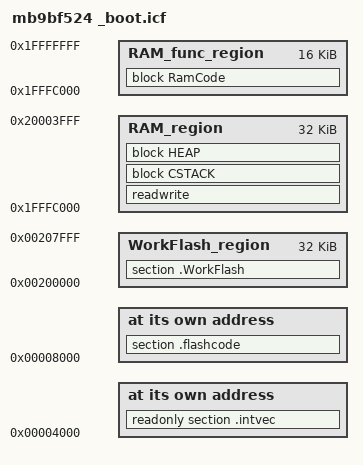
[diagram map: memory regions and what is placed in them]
/*###ICF### Section handled by ICF editor, don't touch! ****/
/*-Editor annotation file-*/
/* IcfEditorFile="$TOOLKIT_DIR$\config\ide\IcfEditor\cortex_v1_0.xml" */
/*-Specials-*/
define symbol __ICFEDIT_intvec_start__ = 0x4000;
/*-Memory Regions-*/
define symbol __ICFEDIT_region_ROM_start__ = 0x4000;
define symbol __ICFEDIT_region_ROM_end__   = 0x00001fff;
define symbol __ICFEDIT_region_RAM_start__ = 0x1FFFC000;
define symbol __ICFEDIT_region_RAM_end__   = 0x20003FFF;

/*-Sizes-*/
define symbol __ICFEDIT_size_cstack__ = 0x400;
define symbol __ICFEDIT_size_heap__   = 0x800;
/**** End of ICF editor section. ###ICF###*/

define symbol WorkFlash_region_start = 0x00200000;
define symbol WorkFlash_region_end   = 0x00207FFF;

define memory mem with size = 4G;
define region ROM_region   = mem:[from __ICFEDIT_region_ROM_start__   to __ICFEDIT_region_ROM_end__];
define region RAM_region   = mem:[from __ICFEDIT_region_RAM_start__   to __ICFEDIT_region_RAM_end__];
define region WorkFlash_region = mem:[from   WorkFlash_region_start       to   WorkFlash_region_end    ];

define symbol __RAM_func_start__   = 0x1FFFC000;		// Add for boot
define symbol __RAM_func_end__     = 0x1FFFFFFF;
define region RAM_func_region =   mem:[from __RAM_func_start__ to __RAM_func_end__];

define block CSTACK    with alignment = 8, size = __ICFEDIT_size_cstack__   { };
define block HEAP      with alignment = 8, size = __ICFEDIT_size_heap__     { };

initialize by copy { readwrite };
do not initialize  { section .noinit };

place at address mem:__ICFEDIT_intvec_start__ { readonly section .intvec };

place in WorkFlash_region { section .WorkFlash };

define block RamCode {section .flash_ram_code};		// Add for boot
place in RAM_func_region  { block RamCode };

place in ROM_region   { readonly };
place in RAM_region   { readwrite,
                        block CSTACK, block HEAP };
place at address mem:0x00008000 { section .flashcode };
